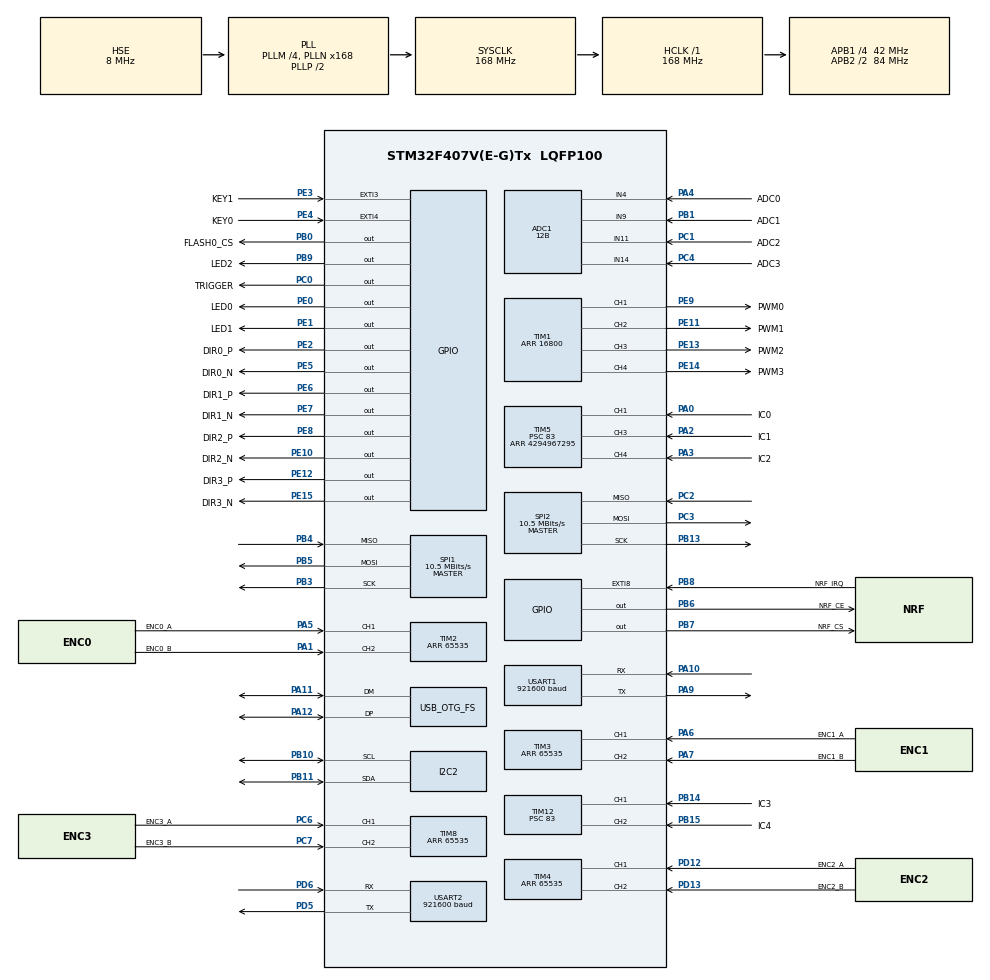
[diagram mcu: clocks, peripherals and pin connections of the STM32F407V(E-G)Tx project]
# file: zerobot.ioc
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ADC1.Channel-0\#ChannelRegularConversion=ADC_CHANNEL_4
ADC1.Channel-5\#ChannelRegularConversion=ADC_CHANNEL_9
ADC1.Channel-6\#ChannelRegularConversion=ADC_CHANNEL_11
ADC1.Channel-7\#ChannelRegularConversion=ADC_CHANNEL_14
ADC1.ClockPrescaler=ADC_CLOCK_SYNC_PCLK_DIV8
ADC1.ContinuousConvMode=DISABLE
ADC1.DMAContinuousRequests=ENABLE
ADC1.DataAlign=ADC_DATAALIGN_RIGHT
ADC1.DiscontinuousConvMode=DISABLE
ADC1.EOCSelection=ADC_EOC_SINGLE_CONV
ADC1.EnableAnalogWatchDog=false
ADC1.ExternalTrigConv=ADC_SOFTWARE_START
ADC1.ExternalTrigConvEdge=ADC_EXTERNALTRIGCONVEDGE_NONE
ADC1.InjNumberOfConversion=0
ADC1.NbrOfConversion=4
ADC1.NbrOfConversionFlag=1
ADC1.Rank-0\#ChannelRegularConversion=1
ADC1.Rank-5\#ChannelRegularConversion=2
ADC1.Rank-6\#ChannelRegularConversion=3
ADC1.Rank-7\#ChannelRegularConversion=4
ADC1.Resolution=ADC_RESOLUTION_12B
ADC1.SamplingTime-0\#ChannelRegularConversion=ADC_SAMPLETIME_480CYCLES
ADC1.SamplingTime-5\#ChannelRegularConversion=ADC_SAMPLETIME_480CYCLES
ADC1.SamplingTime-6\#ChannelRegularConversion=ADC_SAMPLETIME_480CYCLES
ADC1.SamplingTime-7\#ChannelRegularConversion=ADC_SAMPLETIME_480CYCLES
ADC1.ScanConvMode=ENABLE
ADC1.master=1
Dma.ADC1.8.Direction=DMA_PERIPH_TO_MEMORY
Dma.ADC1.8.FIFOMode=DMA_FIFOMODE_DISABLE
Dma.ADC1.8.Instance=DMA2_Stream4
Dma.ADC1.8.MemDataAlignment=DMA_MDATAALIGN_HALFWORD
Dma.ADC1.8.MemInc=DMA_MINC_ENABLE
Dma.ADC1.8.Mode=DMA_NORMAL
Dma.ADC1.8.PeriphDataAlignment=DMA_PDATAALIGN_HALFWORD
Dma.ADC1.8.PeriphInc=DMA_PINC_DISABLE
Dma.ADC1.8.Priority=DMA_PRIORITY_LOW
Dma.Request0=SPI1_RX
Dma.Request1=SPI1_TX
Dma.Request2=USART2_RX
Dma.Request3=USART2_TX
Dma.Request4=SPI2_RX
Dma.Request5=SPI2_TX
Dma.Request6=USART1_RX
Dma.Request7=USART1_TX
Dma.Request8=ADC1
Dma.SPI1_RX.0.Direction=DMA_PERIPH_TO_MEMORY
Dma.SPI1_RX.0.FIFOMode=DMA_FIFOMODE_DISABLE
Dma.SPI1_RX.0.Instance=DMA2_Stream0
Dma.SPI1_RX.0.MemDataAlignment=DMA_MDATAALIGN_BYTE
Dma.SPI1_RX.0.MemInc=DMA_MINC_ENABLE
Dma.SPI1_RX.0.Mode=DMA_NORMAL
Dma.SPI1_RX.0.PeriphDataAlignment=DMA_PDATAALIGN_BYTE
Dma.SPI1_RX.0.PeriphInc=DMA_PINC_DISABLE
Dma.SPI1_RX.0.Priority=DMA_PRIORITY_LOW
Dma.SPI1_TX.1.Direction=DMA_MEMORY_TO_PERIPH
Dma.SPI1_TX.1.FIFOMode=DMA_FIFOMODE_DISABLE
Dma.SPI1_TX.1.Instance=DMA2_Stream3
Dma.SPI1_TX.1.MemDataAlignment=DMA_MDATAALIGN_BYTE
Dma.SPI1_TX.1.MemInc=DMA_MINC_ENABLE
Dma.SPI1_TX.1.Mode=DMA_NORMAL
Dma.SPI1_TX.1.PeriphDataAlignment=DMA_PDATAALIGN_BYTE
Dma.SPI1_TX.1.PeriphInc=DMA_PINC_DISABLE
Dma.SPI1_TX.1.Priority=DMA_PRIORITY_LOW
Dma.SPI2_RX.4.Direction=DMA_PERIPH_TO_MEMORY
Dma.SPI2_RX.4.FIFOMode=DMA_FIFOMODE_DISABLE
Dma.SPI2_RX.4.Instance=DMA1_Stream3
Dma.SPI2_RX.4.MemDataAlignment=DMA_MDATAALIGN_BYTE
Dma.SPI2_RX.4.MemInc=DMA_MINC_ENABLE
Dma.SPI2_RX.4.Mode=DMA_NORMAL
Dma.SPI2_RX.4.PeriphDataAlignment=DMA_PDATAALIGN_BYTE
Dma.SPI2_RX.4.PeriphInc=DMA_PINC_DISABLE
Dma.SPI2_RX.4.Priority=DMA_PRIORITY_LOW
Dma.SPI2_TX.5.Direction=DMA_MEMORY_TO_PERIPH
Dma.SPI2_TX.5.FIFOMode=DMA_FIFOMODE_DISABLE
Dma.SPI2_TX.5.Instance=DMA1_Stream4
Dma.SPI2_TX.5.MemDataAlignment=DMA_MDATAALIGN_BYTE
Dma.SPI2_TX.5.MemInc=DMA_MINC_ENABLE
Dma.SPI2_TX.5.Mode=DMA_NORMAL
Dma.SPI2_TX.5.PeriphDataAlignment=DMA_PDATAALIGN_BYTE
Dma.SPI2_TX.5.PeriphInc=DMA_PINC_DISABLE
Dma.SPI2_TX.5.Priority=DMA_PRIORITY_LOW
Dma.USART1_RX.6.Direction=DMA_PERIPH_TO_MEMORY
Dma.USART1_RX.6.FIFOMode=DMA_FIFOMODE_DISABLE
Dma.USART1_RX.6.Instance=DMA2_Stream2
Dma.USART1_RX.6.MemDataAlignment=DMA_MDATAALIGN_BYTE
Dma.USART1_RX.6.MemInc=DMA_MINC_ENABLE
Dma.USART1_RX.6.Mode=DMA_CIRCULAR
Dma.USART1_RX.6.PeriphDataAlignment=DMA_PDATAALIGN_BYTE
Dma.USART1_RX.6.PeriphInc=DMA_PINC_DISABLE
Dma.USART1_RX.6.Priority=DMA_PRIORITY_LOW
Dma.USART1_TX.7.Direction=DMA_MEMORY_TO_PERIPH
Dma.USART1_TX.7.FIFOMode=DMA_FIFOMODE_DISABLE
Dma.USART1_TX.7.Instance=DMA2_Stream7
Dma.USART1_TX.7.MemDataAlignment=DMA_MDATAALIGN_BYTE
Dma.USART1_TX.7.MemInc=DMA_MINC_ENABLE
Dma.USART1_TX.7.Mode=DMA_NORMAL
Dma.USART1_TX.7.PeriphDataAlignment=DMA_PDATAALIGN_BYTE
Dma.USART1_TX.7.PeriphInc=DMA_PINC_DISABLE
Dma.USART1_TX.7.Priority=DMA_PRIORITY_LOW
Dma.USART2_RX.2.Direction=DMA_PERIPH_TO_MEMORY
Dma.USART2_RX.2.FIFOMode=DMA_FIFOMODE_DISABLE
Dma.USART2_RX.2.Instance=DMA1_Stream5
Dma.USART2_RX.2.MemDataAlignment=DMA_MDATAALIGN_BYTE
Dma.USART2_RX.2.MemInc=DMA_MINC_ENABLE
Dma.USART2_RX.2.Mode=DMA_CIRCULAR
Dma.USART2_RX.2.PeriphDataAlignment=DMA_PDATAALIGN_BYTE
Dma.USART2_RX.2.PeriphInc=DMA_PINC_DISABLE
Dma.USART2_RX.2.Priority=DMA_PRIORITY_LOW
Dma.USART2_TX.3.Direction=DMA_MEMORY_TO_PERIPH
Dma.USART2_TX.3.FIFOMode=DMA_FIFOMODE_DISABLE
Dma.USART2_TX.3.Instance=DMA1_Stream6
Dma.USART2_TX.3.MemDataAlignment=DMA_MDATAALIGN_BYTE
Dma.USART2_TX.3.MemInc=DMA_MINC_ENABLE
Dma.USART2_TX.3.Mode=DMA_NORMAL
Dma.USART2_TX.3.PeriphDataAlignment=DMA_PDATAALIGN_BYTE
Dma.USART2_TX.3.PeriphInc=DMA_PINC_DISABLE
Dma.USART2_TX.3.Priority=DMA_PRIORITY_LOW
FREERTOS.INCLUDE_eTaskGetState=1
FREERTOS.INCLUDE_vTaskCleanUpResources=1
FREERTOS.INCLUDE_vTaskDelayUntil=1
FREERTOS.INCLUDE_vTaskDelete=1
FREERTOS.INCLUDE_xTaskGetCurrentTaskHandle=1
FREERTOS.INCLUDE_xTaskGetHandle=1
FREERTOS.MEMORY_ALLOCATION=0
FREERTOS.Tasks01=loop_task,0,128,loopTaskEntry,As weak,NULL,Dynamic,NULL,NULL
FREERTOS.configENABLE_BACKWARD_COMPATIBILITY=0
FREERTOS.configIDLE_SHOULD_YIELD=0
FREERTOS.configUSE_TASK_NOTIFICATIONS=0
I2C2.I2C_Mode=I2C_Standard
Mcu.Family=STM32F4
Mcu.Name=STM32F407V(E-G)Tx
Mcu.Package=LQFP100
NVIC.DMA1_Stream3_IRQn=true\:5\:0\:false\:false\:true\:true\:false
NVIC.DMA1_Stream4_IRQn=true\:5\:0\:false\:false\:true\:true\:false
NVIC.DMA1_Stream5_IRQn=true\:5\:0\:false\:false\:true\:true\:false
NVIC.DMA1_Stream6_IRQn=true\:5\:0\:false\:false\:true\:true\:false
NVIC.DMA2_Stream0_IRQn=true\:5\:0\:false\:false\:true\:true\:false
NVIC.DMA2_Stream2_IRQn=true\:5\:0\:false\:false\:true\:true\:false
NVIC.DMA2_Stream3_IRQn=true\:5\:0\:false\:false\:true\:true\:false
NVIC.DMA2_Stream4_IRQn=true\:5\:0\:false\:false\:true\:true\:false
NVIC.DMA2_Stream7_IRQn=true\:5\:0\:false\:false\:true\:true\:false
NVIC.EXTI3_IRQn=true\:5\:0\:false\:false\:true\:true\:true
NVIC.EXTI4_IRQn=true\:5\:0\:false\:false\:true\:true\:true
NVIC.EXTI9_5_IRQn=true\:5\:0\:false\:false\:true\:true\:true
NVIC.I2C2_ER_IRQn=true\:5\:0\:false\:false\:true\:true\:true
NVIC.I2C2_EV_IRQn=true\:5\:0\:false\:false\:true\:true\:true
NVIC.PriorityGroup=NVIC_PRIORITYGROUP_4
NVIC.SPI1_IRQn=true\:5\:0\:false\:false\:true\:true\:true
NVIC.SPI2_IRQn=true\:5\:0\:false\:false\:true\:true\:true
NVIC.TIM5_IRQn=true\:5\:0\:false\:false\:true\:true\:true
NVIC.TIM7_IRQn=true\:0\:0\:false\:false\:true\:false\:false
NVIC.TIM8_BRK_TIM12_IRQn=true\:5\:0\:false\:false\:true\:true\:true
NVIC.TimeBase=TIM7_IRQn
NVIC.TimeBaseIP=TIM7
NVIC.USART1_IRQn=true\:5\:0\:false\:false\:true\:true\:true
NVIC.USART2_IRQn=true\:5\:0\:false\:false\:true\:true\:true
PA0-WKUP.GPIO_Label=IC0
PA0-WKUP.GPIO_ModeDefaultPP=GPIO_MODE_AF_OD
PA0-WKUP.GPIO_PuPd=GPIO_PULLDOWN
PA0-WKUP.GPIO_Speed=GPIO_SPEED_FREQ_LOW
PA0-WKUP.Signal=S_TIM5_CH1
PA1.GPIO_Label=ENC0_B
PA1.GPIO_ModeDefaultPP=GPIO_MODE_AF_OD
PA1.GPIO_PuPd=GPIO_NOPULL
PA1.GPIO_Speed=GPIO_SPEED_FREQ_LOW
PA1.Signal=S_TIM2_CH2
PA10.Mode=Asynchronous
PA10.Signal=USART1_RX
PA11.Mode=Device_Only
PA11.Signal=USB_OTG_FS_DM
PA12.Mode=Device_Only
PA12.Signal=USB_OTG_FS_DP
PA13.Mode=Serial_Wire
PA13.Signal=SYS_JTMS-SWDIO
PA14.Mode=Serial_Wire
PA14.Signal=SYS_JTCK-SWCLK
PA2.GPIO_Label=IC1
PA2.GPIO_ModeDefaultPP=GPIO_MODE_AF_OD
PA2.GPIO_PuPd=GPIO_PULLDOWN
PA2.GPIO_Speed=GPIO_SPEED_FREQ_LOW
PA2.Signal=S_TIM5_CH3
PA3.GPIO_Label=IC2
PA3.GPIO_ModeDefaultPP=GPIO_MODE_AF_OD
PA3.GPIO_PuPd=GPIO_PULLDOWN
PA3.GPIO_Speed=GPIO_SPEED_FREQ_LOW
PA3.Signal=S_TIM5_CH4
PA4.GPIO_Label=ADC0
PA4.Signal=ADCx_IN4
PA5.GPIO_Label=ENC0_A
PA5.GPIO_ModeDefaultPP=GPIO_MODE_AF_OD
PA5.GPIO_PuPd=GPIO_NOPULL
PA5.GPIO_Speed=GPIO_SPEED_FREQ_LOW
PA5.Signal=S_TIM2_CH1_ETR
PA6.GPIO_Label=ENC1_A
PA6.GPIO_ModeDefaultPP=GPIO_MODE_AF_OD
PA6.GPIO_PuPd=GPIO_NOPULL
PA6.GPIO_Speed=GPIO_SPEED_FREQ_LOW
PA6.Signal=S_TIM3_CH1
PA7.GPIO_Label=ENC1_B
PA7.GPIO_ModeDefaultPP=GPIO_MODE_AF_OD
PA7.GPIO_PuPd=GPIO_NOPULL
PA7.GPIO_Speed=GPIO_SPEED_FREQ_LOW
PA7.Signal=S_TIM3_CH2
PA9.Mode=Asynchronous
PA9.Signal=USART1_TX
PB0.GPIO_Label=FLASH0_CS
PB0.GPIO_Speed=GPIO_SPEED_FREQ_VERY_HIGH
PB0.PinState=GPIO_PIN_SET
PB0.Signal=GPIO_Output
PB1.GPIO_Label=ADC1
PB1.Signal=ADCx_IN9
PB10.GPIO_PuPdOD=GPIO_PULLUP
PB10.Mode=I2C
PB10.Signal=I2C2_SCL
PB11.GPIO_PuPdOD=GPIO_PULLUP
PB11.Mode=I2C
PB11.Signal=I2C2_SDA
PB13.Mode=Full_Duplex_Master
PB13.Signal=SPI2_SCK
PB14.GPIO_Label=IC3
PB14.GPIO_ModeDefaultPP=GPIO_MODE_AF_OD
PB14.GPIO_PuPd=GPIO_PULLDOWN
PB14.GPIO_Speed=GPIO_SPEED_FREQ_LOW
PB14.Signal=S_TIM12_CH1
PB15.GPIO_Label=IC4
PB15.GPIO_ModeDefaultPP=GPIO_MODE_AF_OD
PB15.GPIO_PuPd=GPIO_PULLDOWN
PB15.GPIO_Speed=GPIO_SPEED_FREQ_LOW
PB15.Signal=S_TIM12_CH2
PB3.Mode=Full_Duplex_Master
PB3.Signal=SPI1_SCK
PB4.Mode=Full_Duplex_Master
PB4.Signal=SPI1_MISO
PB5.Mode=Full_Duplex_Master
PB5.Signal=SPI1_MOSI
PB6.GPIO_Label=NRF_CE
PB6.GPIO_Speed=GPIO_SPEED_FREQ_VERY_HIGH
PB6.PinState=GPIO_PIN_SET
PB6.Signal=GPIO_Output
PB7.GPIO_Label=NRF_CS
PB7.GPIO_Speed=GPIO_SPEED_FREQ_VERY_HIGH
PB7.Signal=GPIO_Output
PB8.GPIO_Label=NRF_IRQ
PB8.GPIO_ModeDefaultEXTI=GPIO_MODE_IT_FALLING
PB8.Signal=GPXTI8
PB9.GPIO_Label=LED2
PB9.GPIO_Speed=GPIO_SPEED_FREQ_LOW
PB9.Signal=GPIO_Output
PC0.GPIO_Label=TRIGGER
PC0.GPIO_ModeDefaultOutputPP=GPIO_MODE_OUTPUT_PP
PC0.GPIO_Speed=GPIO_SPEED_FREQ_LOW
PC0.Signal=GPIO_Output
PC1.GPIO_Label=ADC2
PC1.Signal=ADCx_IN11
PC14-OSC32_IN.Mode=LSE-External-Oscillator
PC14-OSC32_IN.Signal=RCC_OSC32_IN
PC15-OSC32_OUT.Mode=LSE-External-Oscillator
PC15-OSC32_OUT.Signal=RCC_OSC32_OUT
PC2.Mode=Full_Duplex_Master
PC2.Signal=SPI2_MISO
PC3.Mode=Full_Duplex_Master
PC3.Signal=SPI2_MOSI
PC4.GPIO_Label=ADC3
PC4.Signal=ADCx_IN14
PC6.GPIO_Label=ENC3_A
PC6.GPIO_ModeDefaultPP=GPIO_MODE_AF_OD
PC6.GPIO_PuPd=GPIO_NOPULL
PC6.GPIO_Speed=GPIO_SPEED_FREQ_LOW
PC6.Signal=S_TIM8_CH1
PC7.GPIO_Label=ENC3_B
PC7.GPIO_ModeDefaultPP=GPIO_MODE_AF_OD
PC7.GPIO_PuPd=GPIO_NOPULL
PC7.GPIO_Speed=GPIO_SPEED_FREQ_LOW
PC7.Signal=S_TIM8_CH2
PD12.GPIO_Label=ENC2_A
PD12.GPIO_ModeDefaultPP=GPIO_MODE_AF_OD
PD12.GPIO_PuPd=GPIO_NOPULL
PD12.GPIO_Speed=GPIO_SPEED_FREQ_LOW
PD12.Signal=S_TIM4_CH1
PD13.GPIO_Label=ENC2_B
PD13.GPIO_ModeDefaultPP=GPIO_MODE_AF_OD
PD13.GPIO_PuPd=GPIO_NOPULL
PD13.GPIO_Speed=GPIO_SPEED_FREQ_LOW
PD13.Signal=S_TIM4_CH2
PD5.Mode=Asynchronous
PD5.Signal=USART2_TX
PD6.Mode=Asynchronous
PD6.Signal=USART2_RX
PE0.GPIO_Label=LED0
PE0.GPIO_Speed=GPIO_SPEED_FREQ_LOW
PE0.Signal=GPIO_Output
PE1.GPIO_Label=LED1
PE1.GPIO_Speed=GPIO_SPEED_FREQ_LOW
PE1.Signal=GPIO_Output
PE10.GPIO_Label=DIR2_N
PE10.GPIO_ModeDefaultOutputPP=GPIO_MODE_OUTPUT_OD
PE10.GPIO_Speed=GPIO_SPEED_FREQ_LOW
PE10.PinState=GPIO_PIN_SET
PE10.Signal=GPIO_Output
PE11.GPIO_Label=PWM1
PE11.GPIO_ModeDefaultPP=GPIO_MODE_AF_OD
PE11.GPIO_PuPd=GPIO_NOPULL
PE11.GPIO_Speed=GPIO_SPEED_FREQ_LOW
PE11.Signal=S_TIM1_CH2
PE12.GPIO_Label=DIR3_P
PE12.GPIO_ModeDefaultOutputPP=GPIO_MODE_OUTPUT_OD
PE12.GPIO_PuPd=GPIO_NOPULL
PE12.GPIO_Speed=GPIO_SPEED_FREQ_LOW
PE12.PinState=GPIO_PIN_SET
PE12.Signal=GPIO_Output
PE13.GPIO_Label=PWM2
PE13.GPIO_ModeDefaultPP=GPIO_MODE_AF_OD
PE13.GPIO_PuPd=GPIO_NOPULL
PE13.GPIO_Speed=GPIO_SPEED_FREQ_LOW
PE13.Signal=S_TIM1_CH3
PE14.GPIO_Label=PWM3
PE14.GPIO_ModeDefaultPP=GPIO_MODE_AF_OD
PE14.GPIO_PuPd=GPIO_NOPULL
PE14.GPIO_Speed=GPIO_SPEED_FREQ_LOW
PE14.Signal=S_TIM1_CH4
PE15.GPIO_Label=DIR3_N
PE15.GPIO_ModeDefaultOutputPP=GPIO_MODE_OUTPUT_OD
PE15.GPIO_PuPd=GPIO_NOPULL
PE15.GPIO_Speed=GPIO_SPEED_FREQ_LOW
PE15.PinState=GPIO_PIN_SET
PE15.Signal=GPIO_Output
PE2.GPIO_Label=DIR0_P
PE2.GPIO_ModeDefaultOutputPP=GPIO_MODE_OUTPUT_OD
PE2.GPIO_PuPd=GPIO_NOPULL
PE2.GPIO_Speed=GPIO_SPEED_FREQ_LOW
PE2.PinState=GPIO_PIN_SET
PE2.Signal=GPIO_Output
PE3.GPIO_Label=KEY1
PE3.GPIO_ModeDefaultEXTI=GPIO_MODE_IT_FALLING
PE3.GPIO_PuPd=GPIO_PULLUP
PE3.Signal=GPXTI3
PE4.GPIO_Label=KEY0
PE4.GPIO_ModeDefaultEXTI=GPIO_MODE_IT_FALLING
PE4.GPIO_PuPd=GPIO_PULLUP
PE4.Signal=GPXTI4
PE5.GPIO_Label=DIR0_N
PE5.GPIO_ModeDefaultOutputPP=GPIO_MODE_OUTPUT_OD
PE5.GPIO_Speed=GPIO_SPEED_FREQ_LOW
PE5.PinState=GPIO_PIN_SET
PE5.Signal=GPIO_Output
PE6.GPIO_Label=DIR1_P
PE6.GPIO_ModeDefaultOutputPP=GPIO_MODE_OUTPUT_OD
PE6.GPIO_Speed=GPIO_SPEED_FREQ_LOW
PE6.PinState=GPIO_PIN_SET
PE6.Signal=GPIO_Output
PE7.GPIO_Label=DIR1_N
PE7.GPIO_ModeDefaultOutputPP=GPIO_MODE_OUTPUT_OD
PE7.GPIO_Speed=GPIO_SPEED_FREQ_LOW
PE7.PinState=GPIO_PIN_SET
PE7.Signal=GPIO_Output
PE8.GPIO_Label=DIR2_P
PE8.GPIO_ModeDefaultOutputPP=GPIO_MODE_OUTPUT_OD
PE8.GPIO_Speed=GPIO_SPEED_FREQ_LOW
PE8.PinState=GPIO_PIN_SET
PE8.Signal=GPIO_Output
PE9.GPIO_Label=PWM0
PE9.GPIO_ModeDefaultPP=GPIO_MODE_AF_OD
PE9.GPIO_PuPd=GPIO_NOPULL
PE9.GPIO_Speed=GPIO_SPEED_FREQ_LOW
PE9.Signal=S_TIM1_CH1
PH0-OSC_IN.Mode=HSE-External-Oscillator
PH0-OSC_IN.Signal=RCC_OSC_IN
PH1-OSC_OUT.Mode=HSE-External-Oscillator
PH1-OSC_OUT.Signal=RCC_OSC_OUT
ProjectManager.HeapSize=0x800
ProjectManager.StackSize=0x800
ProjectManager.TargetToolchain=TrueSTUDIO
RCC.48MHZClocksFreq_Value=48000000
RCC.AHBFreq_Value=168000000
RCC.APB1CLKDivider=RCC_HCLK_DIV4
RCC.APB1Freq_Value=42000000
RCC.APB1TimFreq_Value=84000000
RCC.APB2CLKDivider=RCC_HCLK_DIV2
RCC.APB2Freq_Value=84000000
RCC.APB2TimFreq_Value=168000000
RCC.CortexFreq_Value=168000000
RCC.HCLKFreq_Value=168000000
RCC.HSE_VALUE=8000000
RCC.HSI_VALUE=16000000
RCC.PLLM=4
RCC.PLLN=168
RCC.PLLQ=7
RCC.SYSCLKFreq_VALUE=168000000
RCC.SYSCLKSource=RCC_SYSCLKSOURCE_PLLCLK
RCC.VCOOutputFreq_Value=336000000
SH.ADCx_IN11.0=ADC1_IN11,IN11
SH.ADCx_IN14.0=ADC1_IN14,IN14
SH.ADCx_IN4.0=ADC1_IN4,IN4
SH.ADCx_IN9.0=ADC1_IN9,IN9
SH.S_TIM12_CH1.0=TIM12_CH1,Input_Capture1_from_TI1
SH.S_TIM12_CH2.0=TIM12_CH2,Input_Capture2_from_TI2
SH.S_TIM1_CH1.0=TIM1_CH1,PWM Generation1 CH1
SH.S_TIM1_CH2.0=TIM1_CH2,PWM Generation2 CH2
SH.S_TIM1_CH3.0=TIM1_CH3,PWM Generation3 CH3
SH.S_TIM1_CH4.0=TIM1_CH4,PWM Generation4 CH4
SH.S_TIM2_CH1_ETR.0=TIM2_CH1,Encoder_Interface
SH.S_TIM2_CH2.0=TIM2_CH2,Encoder_Interface
SH.S_TIM3_CH1.0=TIM3_CH1,Encoder_Interface
SH.S_TIM3_CH2.0=TIM3_CH2,Encoder_Interface
SH.S_TIM4_CH1.0=TIM4_CH1,Encoder_Interface
SH.S_TIM4_CH2.0=TIM4_CH2,Encoder_Interface
SH.S_TIM5_CH1.0=TIM5_CH1,Input_Capture1_from_TI1
SH.S_TIM5_CH3.0=TIM5_CH3,Input_Capture3_from_TI3
SH.S_TIM5_CH4.0=TIM5_CH4,Input_Capture4_from_TI4
SH.S_TIM8_CH1.0=TIM8_CH1,Encoder_Interface
SH.S_TIM8_CH2.0=TIM8_CH2,Encoder_Interface
SPI1.BaudRatePrescaler=SPI_BAUDRATEPRESCALER_8
SPI1.CalculateBaudRate=10.5 MBits/s
SPI1.Direction=SPI_DIRECTION_2LINES
SPI1.Mode=SPI_MODE_MASTER
SPI1.VirtualType=VM_MASTER
SPI2.BaudRatePrescaler=SPI_BAUDRATEPRESCALER_4
SPI2.CalculateBaudRate=10.5 MBits/s
SPI2.Direction=SPI_DIRECTION_2LINES
SPI2.Mode=SPI_MODE_MASTER
SPI2.VirtualType=VM_MASTER
TIM1.Channel-PWM\ Generation1\ CH1=TIM_CHANNEL_1
TIM1.Channel-PWM\ Generation2\ CH2=TIM_CHANNEL_2
TIM1.Channel-PWM\ Generation3\ CH3=TIM_CHANNEL_3
TIM1.Channel-PWM\ Generation4\ CH4=TIM_CHANNEL_4
TIM1.Period=16800
TIM12.Channel-Input_Capture1_from_TI1=TIM_CHANNEL_1
TIM12.Channel-Input_Capture2_from_TI2=TIM_CHANNEL_2
TIM12.Period=65535
TIM12.Prescaler=83
TIM2.EncoderMode=TIM_ENCODERMODE_TI12
TIM2.Period=65535
TIM3.EncoderMode=TIM_ENCODERMODE_TI12
TIM3.Period=65535
TIM4.EncoderMode=TIM_ENCODERMODE_TI12
TIM4.Period=65535
TIM5.Channel-Input_Capture1_from_TI1=TIM_CHANNEL_1
TIM5.Channel-Input_Capture3_from_TI3=TIM_CHANNEL_3
TIM5.Channel-Input_Capture4_from_TI4=TIM_CHANNEL_4
TIM5.Period=4294967295
TIM5.Prescaler=83
TIM8.EncoderMode=TIM_ENCODERMODE_TI12
TIM8.Period=65535
USART1.BaudRate=921600
USART1.VirtualMode=VM_ASYNC
USART2.BaudRate=921600
USART2.VirtualMode=VM_ASYNC
USB_OTG_FS.VirtualMode=Device_Only
VP_FREERTOS_VS_ENABLE.Mode=Enabled
VP_SYS_VS_tim7.Mode=TIM7
board=zerobot

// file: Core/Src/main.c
/* USER CODE BEGIN Header */
/**
  ******************************************************************************
  * @file           : main.c
  * @brief          : Main program body
  ******************************************************************************
  * This notice applies to any and all portions of this file
  * that are not between comment pairs USER CODE BEGIN and
  * USER CODE END. Other portions of this file, whether
  * inserted by the user or by software development tools
  * are owned by their respective copyright owners.
  *
  * Copyright (c) 2018 STMicroelectronics International N.V.
  * All rights reserved.
  *
  * Redistribution and use in source and binary forms, with or without
  * modification, are permitted, provided that the following conditions are met:
  *
  * 1. Redistribution of source code must retain the above copyright notice,
  *    this list of conditions and the following disclaimer.
  * 2. Redistributions in binary form must reproduce the above copyright notice,
  *    this list of conditions and the following disclaimer in the documentation
  *    and/or other materials provided with the distribution.
  * 3. Neither the name of STMicroelectronics nor the names of other
  *    contributors to this software may be used to endorse or promote products
  *    derived from this software without specific written permission.
  * 4. This software, including modifications and/or derivative works of this
  *    software, must execute solely and exclusively on microcontroller or
  *    microprocessor devices manufactured by or for STMicroelectronics.
  * 5. Redistribution and use of this software other than as permitted under
  *    this license is void and will automatically terminate your rights under
  *    this license.
  *
  * THIS SOFTWARE IS PROVIDED BY STMICROELECTRONICS AND CONTRIBUTORS "AS IS"
  * AND ANY EXPRESS, IMPLIED OR STATUTORY WARRANTIES, INCLUDING, BUT NOT
  * LIMITED TO, THE IMPLIED WARRANTIES OF MERCHANTABILITY, FITNESS FOR A
  * PARTICULAR PURPOSE AND NON-INFRINGEMENT OF THIRD PARTY INTELLECTUAL PROPERTY
  * RIGHTS ARE DISCLAIMED TO THE FULLEST EXTENT PERMITTED BY LAW. IN NO EVENT
  * SHALL STMICROELECTRONICS OR CONTRIBUTORS BE LIABLE FOR ANY DIRECT, INDIRECT,
  * INCIDENTAL, SPECIAL, EXEMPLARY, OR CONSEQUENTIAL DAMAGES (INCLUDING, BUT NOT
  * LIMITED TO, PROCUREMENT OF SUBSTITUTE GOODS OR SERVICES; LOSS OF USE, DATA,
  * OR PROFITS; OR BUSINESS INTERRUPTION) HOWEVER CAUSED AND ON ANY THEORY OF
  * LIABILITY, WHETHER IN CONTRACT, STRICT LIABILITY, OR TORT (INCLUDING
  * NEGLIGENCE OR OTHERWISE) ARISING IN ANY WAY OUT OF THE USE OF THIS SOFTWARE,
  * EVEN IF ADVISED OF THE POSSIBILITY OF SUCH DAMAGE.
  *
  ******************************************************************************
  */
/* USER CODE END Header */

#include "main.h"
#include "cmsis_os.h"
#include "adc.h"
#include "dma.h"
#include "i2c.h"
#include "spi.h"
#include "tim.h"
#include "usart.h"
#include "usb_otg.h"
#include "gpio.h"

void SystemClock_Config(void);
void MX_FREERTOS_Init(void);

int main(void)
{

  /* MCU Configuration--------------------------------------------------------*/

  /* Reset of all peripherals, Initializes the Flash interface and the Systick. */
  HAL_Init();

  /* Configure the system clock */
  SystemClock_Config();

  /* USER CODE BEGIN SysInit */
  HAL_I2C_MspInit(&hi2c2);
  /* USER CODE END SysInit */

  /* Initialize all configured peripherals */
  MX_GPIO_Init();
  MX_DMA_Init();
  MX_USART1_UART_Init();
  MX_SPI1_Init();
  MX_USB_OTG_FS_PCD_Init();
  MX_TIM1_Init();
  MX_TIM2_Init();
  MX_TIM3_Init();
  MX_TIM4_Init();
  MX_USART2_UART_Init();
  MX_TIM8_Init();
  MX_TIM5_Init();
  MX_I2C2_Init();
  MX_SPI2_Init();
  MX_TIM12_Init();
  MX_ADC1_Init();
  /* USER CODE BEGIN 2 */
  void appInit(void);
  appInit();
  /* USER CODE END 2 */

  /* Call init function for freertos objects (in freertos.c) */
  MX_FREERTOS_Init();

  /* Start scheduler */
  osKernelStart();

  /* We should never get here as control is now taken by the scheduler */

  /* Infinite loop */
  while (1)
  {

  }
}

void SystemClock_Config(void)
{
  RCC_OscInitTypeDef RCC_OscInitStruct = {0};
  RCC_ClkInitTypeDef RCC_ClkInitStruct = {0};

  /**Configure the main internal regulator output voltage
  */
  __HAL_RCC_PWR_CLK_ENABLE();
  __HAL_PWR_VOLTAGESCALING_CONFIG(PWR_REGULATOR_VOLTAGE_SCALE1);
  /**Initializes the CPU, AHB and APB busses clocks
  */
  RCC_OscInitStruct.OscillatorType = RCC_OSCILLATORTYPE_LSI|RCC_OSCILLATORTYPE_HSE;
  RCC_OscInitStruct.HSEState = RCC_HSE_ON;
  RCC_OscInitStruct.LSIState = RCC_LSI_ON;
  RCC_OscInitStruct.PLL.PLLState = RCC_PLL_ON;
  RCC_OscInitStruct.PLL.PLLSource = RCC_PLLSOURCE_HSE;
  RCC_OscInitStruct.PLL.PLLM = 4;
  RCC_OscInitStruct.PLL.PLLN = 168;
  RCC_OscInitStruct.PLL.PLLP = RCC_PLLP_DIV2;
  RCC_OscInitStruct.PLL.PLLQ = 7;
  if (HAL_RCC_OscConfig(&RCC_OscInitStruct) != HAL_OK)
  {
    Error_Handler();
  }
  /**Initializes the CPU, AHB and APB busses clocks
  */
  RCC_ClkInitStruct.ClockType = RCC_CLOCKTYPE_HCLK|RCC_CLOCKTYPE_SYSCLK
                              |RCC_CLOCKTYPE_PCLK1|RCC_CLOCKTYPE_PCLK2;
  RCC_ClkInitStruct.SYSCLKSource = RCC_SYSCLKSOURCE_PLLCLK;
  RCC_ClkInitStruct.AHBCLKDivider = RCC_SYSCLK_DIV1;
  RCC_ClkInitStruct.APB1CLKDivider = RCC_HCLK_DIV4;
  RCC_ClkInitStruct.APB2CLKDivider = RCC_HCLK_DIV2;

  if (HAL_RCC_ClockConfig(&RCC_ClkInitStruct, FLASH_LATENCY_5) != HAL_OK)
  {
    Error_Handler();
  }
}

void HAL_TIM_PeriodElapsedCallback(TIM_HandleTypeDef *htim)
{
  if (htim->Instance == TIM7) {
    HAL_IncTick();
  }
}

void Error_Handler(void)
{
}

/************************ (C) COPYRIGHT STMicroelectronics *****END OF FILE****/

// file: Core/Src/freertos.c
/* USER CODE BEGIN Header */
/**
  ******************************************************************************
  * File Name          : freertos.c
  * Description        : Code for freertos applications
  ******************************************************************************
  * This notice applies to any and all portions of this file
  * that are not between comment pairs USER CODE BEGIN and
  * USER CODE END. Other portions of this file, whether
  * inserted by the user or by software development tools
  * are owned by their respective copyright owners.
  *
  * Copyright (c) 2018 STMicroelectronics International N.V.
  * All rights reserved.
  *
  * Redistribution and use in source and binary forms, with or without
  * modification, are permitted, provided that the following conditions are met:
  *
  * 1. Redistribution of source code must retain the above copyright notice,
  *    this list of conditions and the following disclaimer.
  * 2. Redistributions in binary form must reproduce the above copyright notice,
  *    this list of conditions and the following disclaimer in the documentation
  *    and/or other materials provided with the distribution.
  * 3. Neither the name of STMicroelectronics nor the names of other
  *    contributors to this software may be used to endorse or promote products
  *    derived from this software without specific written permission.
  * 4. This software, including modifications and/or derivative works of this
  *    software, must execute solely and exclusively on microcontroller or
  *    microprocessor devices manufactured by or for STMicroelectronics.
  * 5. Redistribution and use of this software other than as permitted under
  *    this license is void and will automatically terminate your rights under
  *    this license.
  *
  * THIS SOFTWARE IS PROVIDED BY STMICROELECTRONICS AND CONTRIBUTORS "AS IS"
  * AND ANY EXPRESS, IMPLIED OR STATUTORY WARRANTIES, INCLUDING, BUT NOT
  * LIMITED TO, THE IMPLIED WARRANTIES OF MERCHANTABILITY, FITNESS FOR A
  * PARTICULAR PURPOSE AND NON-INFRINGEMENT OF THIRD PARTY INTELLECTUAL PROPERTY
  * RIGHTS ARE DISCLAIMED TO THE FULLEST EXTENT PERMITTED BY LAW. IN NO EVENT
  * SHALL STMICROELECTRONICS OR CONTRIBUTORS BE LIABLE FOR ANY DIRECT, INDIRECT,
  * INCIDENTAL, SPECIAL, EXEMPLARY, OR CONSEQUENTIAL DAMAGES (INCLUDING, BUT NOT
  * LIMITED TO, PROCUREMENT OF SUBSTITUTE GOODS OR SERVICES; LOSS OF USE, DATA,
  * OR PROFITS; OR BUSINESS INTERRUPTION) HOWEVER CAUSED AND ON ANY THEORY OF
  * LIABILITY, WHETHER IN CONTRACT, STRICT LIABILITY, OR TORT (INCLUDING
  * NEGLIGENCE OR OTHERWISE) ARISING IN ANY WAY OUT OF THE USE OF THIS SOFTWARE,
  * EVEN IF ADVISED OF THE POSSIBILITY OF SUCH DAMAGE.
  *
  ******************************************************************************
  */
/* USER CODE END Header */

#include "FreeRTOS.h"
#include "task.h"
#include "main.h"
#include "cmsis_os.h"

osThreadId loop_taskHandle;

void loopTaskEntry(void const * argument);

void MX_FREERTOS_Init(void); /* (MISRA C 2004 rule 8.1) */

void MX_FREERTOS_Init(void) {

  /* Create the thread(s) */
  /* definition and creation of loop_task */
  osThreadDef(loop_task, loopTaskEntry, osPriorityNormal, 0, 128);
  loop_taskHandle = osThreadCreate(osThread(loop_task), NULL);

}

__weak void loopTaskEntry(void const * argument)
{

  for(;;)
  {
    osDelay(1);
  }
}

/************************ (C) COPYRIGHT STMicroelectronics *****END OF FILE****/
